# CC1314R10 register map
File version: 1.0
CPU: CM33 1.0, other endian, MPU, FPU, 3 interrupt priority bits
Registers are 32-bit, read-write, reset 0x0 unless marked. A register's access mark holds for its fields unless they carry their own. Offsets are from the block's base; [hi:lo] are bit positions.

## CPU_FPU — Cortex-M's Floating Point Unit (FPU)
Base 0xE000EF30
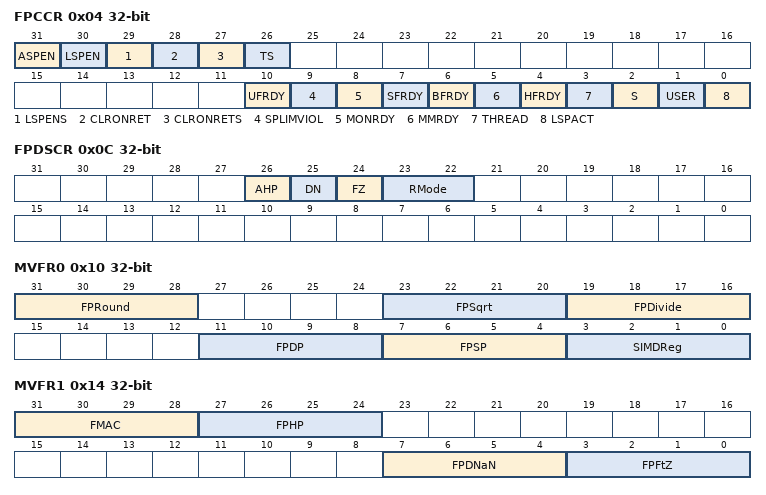
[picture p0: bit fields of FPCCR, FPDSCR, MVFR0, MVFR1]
0x04 FPCCR — Holds control data for the Floating-point extension
  [31] ASPEN — [31:31] When this bit is set to 1, execution of a floating-point instruction sets the CONTROL.FPCA bit to 1
  [30] LSPEN — [30:30] Enables lazy context save of floating-point state
  [29] LSPENS — [29:29] This bit controls whether the LSPEN bit is writeable from the Non-secure state
  [28] CLRONRET — [28:28] Clear floating-point caller saved registers on exception return
  [27] CLRONRETS — [27:27] This bit controls whether the CLRONRET bit is writeable from the Non-secure state
  [26] TS — [26:26] Treat floating-point registers as Secure enable
  [10] UFRDY — [10:10] Indicates whether the software executing when the PE allocated the floating-point stack frame was able to set the UsageFault exception to pending
  [9] SPLIMVIOL — [9:9] This bit is banked between the Security states and indicates whether the floating-point context violates the stack pointer limit that was active when lazy state preservation was activated. SPLIMVIOL modifies the lazy floating-point state preservation behavior
  [8] MONRDY — [8:8] Indicates whether the software executing when the PE allocated the floating-point stack frame was able to set the DebugMonitor exception to pending
  [7] SFRDY — [7:7] Indicates whether the software executing when the PE allocated the floating-point stack frame was able to set the SecureFault exception to pending. This bit is only present in the Secure version of the register, and behaves as RAZ/WI when accessed from the Non-secure state
  [6] BFRDY — [6:6] Indicates whether the software executing when the PE allocated the floating-point stack frame was able to set the BusFault exception to pending
  [5] MMRDY — [5:5] Indicates whether the software executing when the PE allocated the floating-point stack frame was able to set the MemManage exception to pending
  [4] HFRDY — [4:4] Indicates whether the software executing when the PE allocated the floating-point stack frame was able to set the HardFault exception to pending
  [3] THREAD — [3:3] Indicates the PE mode when it allocated the floating-point stack frame
  [2] S — [2:2] Security status of the floating-point context. This bit is only present in the Secure version of the register, and behaves as RAZ/WI when accessed from the Non-secure state. This bit is updated whenever lazy state preservation is activated, or when a floating-point instruction is executed
  [1] USER — [1:1] Indicates the privilege level of the software executing when the PE allocated the floating-point stack frame
  [0] LSPACT — [0:0] Indicates whether lazy preservation of the floating-point state is active
0x08 FPCAR — Holds the location of the unpopulated floating-point register space allocated on an exception stack frame
  [31:3] ADDRESS — [31:3] The location of the unpopulated floating-point register space allocated on an exception stack frame
0x0C FPDSCR — Holds the default values for the floating-point status control data that the PE assigns to the FPSCR when it creates a new floating-point context
  [26] AHP — [26:26] Default value for FPSCR.AHP
  [25] DN — [25:25] Default value for FPSCR.DN
  [24] FZ — [24:24] Default value for FPSCR.FZ
  [23:22] RMode — [23:22] Default value for FPSCR.RMode
0x10 MVFR0 — Describes the features provided by the Floating-point Extension
  [31:28] FPRound ro — [31:28] Indicates the rounding modes supported by the FP Extension
  [23:20] FPSqrt ro — [23:20] Indicates the support for FP square root operations
  [19:16] FPDivide ro — [19:16] Indicates the support for FP divide operations
  [11:8] FPDP ro — [11:8] Indicates support for FP double-precision operations
  [7:4] FPSP ro — [7:4] Indicates support for FP single-precision operations
  [3:0] SIMDReg ro — [3:0] Indicates size of FP register file
0x14 MVFR1 — Describes the features provided by the Floating-point Extension
  [31:28] FMAC ro — [31:28] Indicates whether the FP Extension implements the fused multiply accumulate instructions
  [27:24] FPHP ro — [27:24] Indicates whether the FP Extension implements half-precision FP conversion instructions
  [7:4] FPDNaN ro — [7:4] Indicates whether the FP hardware implementation supports NaN propagation
  [3:0] FPFtZ ro — [3:0] Indicates whether subnormals are always flushed-to-zero
0x18 MVFR2 — Describes the features provided by the Floating-point Extension
  [7:4] FPMisc ro — [7:4] Indicates support for miscellaneous FP features
